# STMP3770 register map
Vendor: Freescale Semiconductor (NXP); Series: STMP37xx; File version: 1.0
CPU: other r0p0, little endian, no MPU, no FPU, 2 interrupt priority bits
Registers are 32-bit, read-write, reset 0x0 unless marked. A register's access mark holds for its fields unless they carry their own. Offsets are from the block's base; [hi:lo] are bit positions.

## I2C — I2C 总线控制器，支持主从模式、PIO/DMA 数据传输、可编程时序与多主机仲裁。
Base 0x80058000
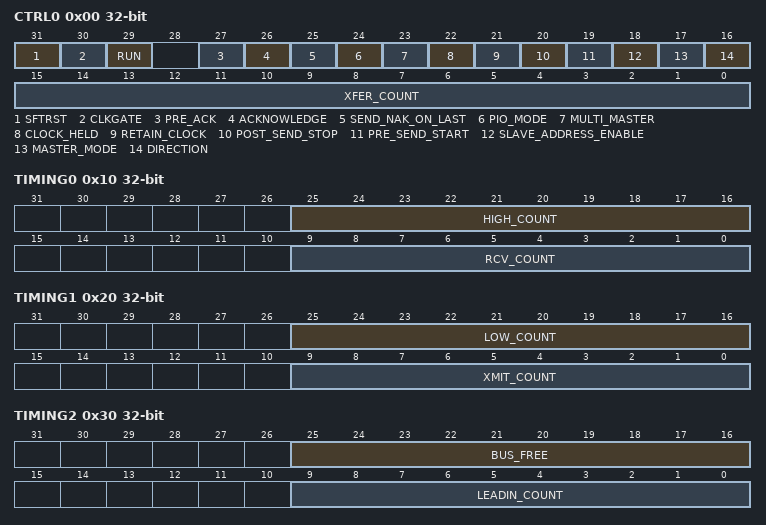
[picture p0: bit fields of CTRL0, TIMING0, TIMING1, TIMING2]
0x00 CTRL0 — I2C 控制寄存器 0，配置传输方向、主从模式、字节数、START/STOP 条件、PIO 模式、时钟门控与软复位等核心参数。
  [31] SFTRST — 软复位：0=正常运行，1=复位整个 I2C 模块。
    0=RUN; 1=RESET
  [30] CLKGATE — 时钟门控：0=正常时钟，1=关闭时钟以节能。
    0=RUN; 1=NO_CLKS
  [29] RUN — 控制器运行控制：0=停止，1=运行。
    0=HALT; 1=RUN
  [27] PRE_ACK — 预应答控制，用于在时钟保持前提前产生 ACK。
  [26] ACKNOWLEDGE — 应答控制：0=发送 NAK，1=发送 ACK。
    0=SNAK; 1=ACK
  [25] SEND_NAK_ON_LAST — 最后一字节是否发送 NAK：0=ACK，1=NAK。
    0=ACK_IT; 1=NAK_IT
  [24] PIO_MODE — PIO 模式使能，用于软件直接控制数据读写。
  [23] MULTI_MASTER — 多主机模式：0=单主机，1=多主机。
    0=SINGLE; 1=MULTIPLE
  [22] CLOCK_HELD — 时钟保持状态：0=释放，1=保持低电平。
    0=RELEASE; 1=HELD_LOW
  [21] RETAIN_CLOCK — 保持 SCL 低电平：0=释放，1=保持低电平。
    0=RELEASE; 1=HOLD_LOW
  [20] POST_SEND_STOP — 传输后是否发送 STOP 条件：0=不发，1=发送 STOP。
    0=NO_STOP; 1=SEND_STOP
  [19] PRE_SEND_START — 传输前是否发送 START 条件：0=不发，1=发送 START。
    0=NO_START; 1=SEND_START
  [18] SLAVE_ADDRESS_ENABLE — 从机地址匹配使能：0=禁用，1=使能。
    0=DISABLED; 1=ENABLED
  [17] MASTER_MODE — 主从模式选择：0=从机，1=主机。
    0=SLAVE; 1=MASTER
  [16] DIRECTION — 传输方向：0=接收，1=发送。
    0=RECEIVE; 1=TRANSMIT
  [15:0] XFER_COUNT — 本次传输的字节数（16 位）。
0x10 TIMING0 — I2C 时序寄存器 0，配置 SCL 高电平周期与接收采样计数。
  [25:16] HIGH_COUNT — SCL 高电平周期计数，决定 SCL 保持高电平的时钟周期数。
  [9:0] RCV_COUNT — 接收采样计数，用于控制接收数据位的采样时序。
0x20 TIMING1 — I2C 时序寄存器 1，配置 SCL 低电平周期与发送采样计数。
  [25:16] LOW_COUNT — SCL 低电平周期计数，决定 SCL 保持低电平的时钟周期数。
  [9:0] XMIT_COUNT — 发送采样计数，用于控制发送数据位的时序。
0x30 TIMING2 — I2C 时序寄存器 2，配置引导计数与总线空闲时间。
  [25:16] BUS_FREE — 总线空闲时间计数，定义两次传输之间总线必须保持空闲的最小时钟周期数。
  [9:0] LEADIN_COUNT — 引导计数，用于 START 条件前的引导时序。
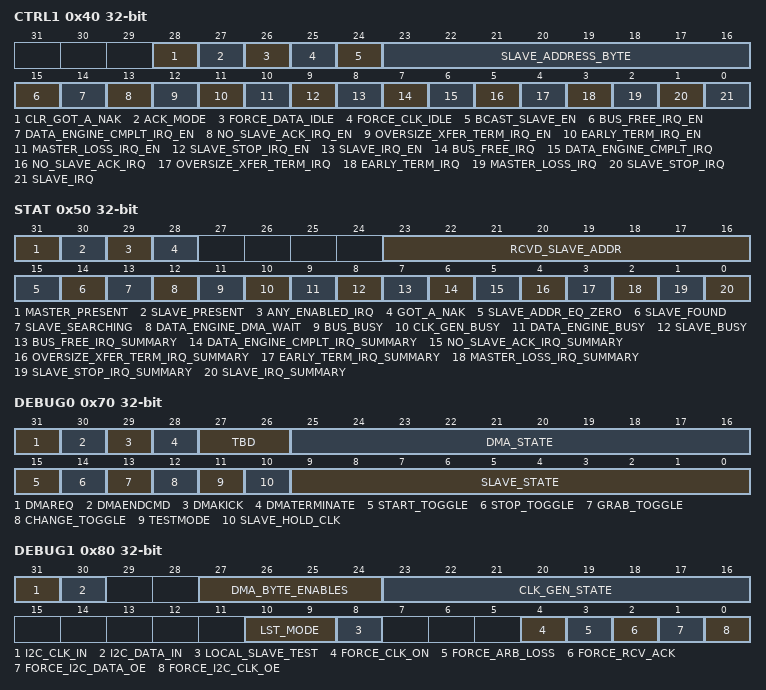
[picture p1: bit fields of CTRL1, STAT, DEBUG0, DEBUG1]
0x40 CTRL1 — I2C 控制寄存器 1，配置各类中断状态/使能、从机地址、广播监听、ACK 模式及清除 NAK 标志。
  [28] CLR_GOT_A_NAK — 清除 GOT_A_NAK 标志：0=无操作，1=清除标志。
    0=DO_NOTHING; 1=CLEAR
  [27] ACK_MODE — ACK 模式：0=在时钟保持低后应答，1=在时钟保持低前应答。
    0=ACK_AFTER_HOLD_LOW; 1=ACK_BEFORE_HOLD_LOW
  [26] FORCE_DATA_IDLE — 强制 SDA 空闲，用于调试时强制数据线进入空闲状态。
  [25] FORCE_CLK_IDLE — 强制 SCL 空闲，用于调试时强制时钟线进入空闲状态。
  [24] BCAST_SLAVE_EN — 广播地址监听：0=忽略广播，1=监听广播地址。
    0=NO_BCAST; 1=WATCH_BCAST
  [23:16] SLAVE_ADDRESS_BYTE — 从机地址字节（8 位），用于配置本机从机地址。
  [15] BUS_FREE_IRQ_EN — 总线空闲中断使能：0=禁用，1=使能。
    0=DISABLED; 1=ENABLED
  [14] DATA_ENGINE_CMPLT_IRQ_EN — 数据引擎完成中断使能：0=禁用，1=使能。
    0=DISABLED; 1=ENABLED
  [13] NO_SLAVE_ACK_IRQ_EN — 无从机应答中断使能：0=禁用，1=使能。
    0=DISABLED; 1=ENABLED
  [12] OVERSIZE_XFER_TERM_IRQ_EN — 超长传输终止中断使能：0=禁用，1=使能。
    0=DISABLED; 1=ENABLED
  [11] EARLY_TERM_IRQ_EN — 提前终止中断使能：0=禁用，1=使能。
    0=DISABLED; 1=ENABLED
  [10] MASTER_LOSS_IRQ_EN — 主机仲裁丢失中断使能：0=禁用，1=使能。
    0=DISABLED; 1=ENABLED
  [9] SLAVE_STOP_IRQ_EN — 从机 STOP 中断使能：0=禁用，1=使能。
    0=DISABLED; 1=ENABLED
  [8] SLAVE_IRQ_EN — 从机访问中断使能：0=禁用，1=使能。
    0=DISABLED; 1=ENABLED
  [7] BUS_FREE_IRQ — 总线空闲中断状态：0=无请求，1=有请求。
    0=NO_REQUEST; 1=REQUEST
  [6] DATA_ENGINE_CMPLT_IRQ — 数据引擎完成中断状态：0=无请求，1=有请求。
    0=NO_REQUEST; 1=REQUEST
  [5] NO_SLAVE_ACK_IRQ — 无从机应答中断状态：0=无请求，1=有请求。
    0=NO_REQUEST; 1=REQUEST
  [4] OVERSIZE_XFER_TERM_IRQ — 超长传输终止中断状态：0=无请求，1=有请求。
    0=NO_REQUEST; 1=REQUEST
  [3] EARLY_TERM_IRQ — 提前终止中断状态：0=无请求，1=有请求。
    0=NO_REQUEST; 1=REQUEST
  [2] MASTER_LOSS_IRQ — 主机仲裁丢失中断状态：0=无请求，1=有请求。
    0=NO_REQUEST; 1=REQUEST
  [1] SLAVE_STOP_IRQ — 从机 STOP 中断状态：0=无请求，1=有请求。
    0=NO_REQUEST; 1=REQUEST
  [0] SLAVE_IRQ — 从机访问中断状态：0=无请求，1=有请求。
    0=NO_REQUEST; 1=REQUEST
0x50 STAT — I2C 状态寄存器，反映各类中断汇总、总线/引擎/时钟忙状态、从机搜索状态及接收到的从机地址等信息。
  [31] MASTER_PRESENT — 主机功能存在标志：0=不可用，1=可用。
    0=UNAVAILABLE; 1=AVAILABLE
  [30] SLAVE_PRESENT — 从机功能存在标志：0=不可用，1=可用。
    0=UNAVAILABLE; 1=AVAILABLE
  [29] ANY_ENABLED_IRQ — 任意已使能中断请求：0=无请求，1=至少有一个中断请求。
    0=NO_REQUESTS; 1=AT_LEAST_ONE_REQUEST
  [28] GOT_A_NAK — 检测到 NAK 标志：0=未检测到，1=检测到 NAK。
    0=NO_NAK; 1=DETECTED_NAK
  [23:16] RCVD_SLAVE_ADDR — 接收到的从机地址字节（8 位）。
  [15] SLAVE_ADDR_EQ_ZERO — 接收到的从机地址是否为 0：0=未匹配到 0，1=地址为 0。
    0=ZERO_NOT_MATCHED; 1=WAS_ZERO
  [14] SLAVE_FOUND — 从机地址匹配结果：0=空闲，1=已匹配并等待。
    0=IDLE; 1=WAITING
  [13] SLAVE_SEARCHING — 从机地址搜索状态：0=空闲，1=正在搜索。
    0=IDLE; 1=ACTIVE
  [12] DATA_ENGINE_DMA_WAIT — 数据引擎 DMA 等待状态：0=继续，1=等待 DMA。
    0=CONTINUE; 1=WAITING
  [11] BUS_BUSY — 总线忙状态：0=空闲，1=忙。
    0=IDLE; 1=BUSY
  [10] CLK_GEN_BUSY — 时钟生成器忙状态：0=空闲，1=忙。
    0=IDLE; 1=BUSY
  [9] DATA_ENGINE_BUSY — 数据引擎忙状态：0=空闲，1=忙。
    0=IDLE; 1=BUSY
  [8] SLAVE_BUSY — 从机引擎忙状态：0=空闲，1=忙。
    0=IDLE; 1=BUSY
  [7] BUS_FREE_IRQ_SUMMARY — 总线空闲中断汇总：0=无请求，1=有请求。
    0=NO_REQUEST; 1=REQUEST
  [6] DATA_ENGINE_CMPLT_IRQ_SUMMARY — 数据引擎完成中断汇总：0=无请求，1=有请求。
    0=NO_REQUEST; 1=REQUEST
  [5] NO_SLAVE_ACK_IRQ_SUMMARY — 无从机应答中断汇总：0=无请求，1=有请求。
    0=NO_REQUEST; 1=REQUEST
  [4] OVERSIZE_XFER_TERM_IRQ_SUMMARY — 超长传输终止中断汇总：0=无请求，1=有请求。
    0=NO_REQUEST; 1=REQUEST
  [3] EARLY_TERM_IRQ_SUMMARY — 提前终止中断汇总：0=无请求，1=有请求。
    0=NO_REQUEST; 1=REQUEST
  [2] MASTER_LOSS_IRQ_SUMMARY — 主机仲裁丢失中断汇总：0=无请求，1=有请求。
    0=NO_REQUEST; 1=REQUEST
  [1] SLAVE_STOP_IRQ_SUMMARY — 从机 STOP 中断汇总：0=无请求，1=有请求。
    0=NO_REQUEST; 1=REQUEST
  [0] SLAVE_IRQ_SUMMARY — 从机访问中断汇总：0=无请求，1=有请求。
    0=NO_REQUEST; 1=REQUEST
0x60 DATA — I2C 数据寄存器，用于 PIO 模式下读写传输数据，或作为 DMA 数据接口。
  [31:0] DATA — PIO/DMA 数据读写端口（32 位），写操作发送数据，读操作接收数据。
0x70 DEBUG0 ro — I2C 调试寄存器 0，提供从机状态机、DMA 状态机、各类事件翻转位及 DMA 控制信号的调试可见性。
  [31] DMAREQ — DMA 请求信号，用于调试时观察 DMA 请求状态。
  [30] DMAENDCMD — DMA 结束命令信号，用于调试时观察 DMA 命令结束状态。
  [29] DMAKICK — DMA 启动信号，用于调试时观察 DMA 传输启动状态。
  [28] DMATERMINATE — DMA 终止信号，用于调试时观察 DMA 传输终止状态。
  [27:26] TBD — 保留位（2 位），供未来扩展或内部测试使用。
  [25:16] DMA_STATE — DMA 状态机当前状态（10 位）。
  [15] START_TOGGLE — START 事件翻转位，用于调试时观察 START 条件事件。
  [14] STOP_TOGGLE — STOP 事件翻转位，用于调试时观察 STOP 条件事件。
  [13] GRAB_TOGGLE — GRAB 事件翻转位，用于调试时观察总线占用事件。
  [12] CHANGE_TOGGLE — CHANGE 事件翻转位，用于调试时观察状态变化事件。
  [11] TESTMODE — 测试模式使能，用于芯片测试时的特殊模式。
  [10] SLAVE_HOLD_CLK — 从机时钟保持状态：0=未保持，1=正在保持 SCL 低电平。
  [9:0] SLAVE_STATE — 从机状态机当前状态（10 位）。
0x80 DEBUG1 ro — I2C 调试寄存器 1，提供强制信号注入、从机测试模式、时钟生成器状态、DMA 字节使能及 I2C 引脚输入状态的调试可见性。
  [31] I2C_CLK_IN — I2C 时钟输入引脚（SCL）的当前电平状态。
  [30] I2C_DATA_IN — I2C 数据输入引脚（SDA）的当前电平状态。
  [27:24] DMA_BYTE_ENABLES — DMA 字节使能掩码（4 位），指示当前 DMA 传输中哪些字节有效。
  [23:16] CLK_GEN_STATE — 时钟生成器状态机当前状态（8 位）。
  [10:9] LST_MODE — 从机监听传输模式：0=广播，1=本机写，2=本机读，3=非本机。
    0=BCAST; 1=MY_WRITE; 2=MY_READ; 3=NOT_ME
  [8] LOCAL_SLAVE_TEST — 本地从机测试模式使能，用于芯片测试时启用内部从机测试逻辑。
  [4] FORCE_CLK_ON — 强制时钟开启，用于调试时强制使能时钟生成器。
  [3] FORCE_ARB_LOSS — 强制仲裁丢失，用于调试时模拟仲裁丢失场景。
  [2] FORCE_RCV_ACK — 强制接收 ACK，用于调试时手动注入 ACK 信号。
  [1] FORCE_I2C_DATA_OE — 强制 I2C 数据输出使能，用于调试时手动控制 SDA 输出。
  [0] FORCE_I2C_CLK_OE — 强制 I2C 时钟输出使能，用于调试时手动控制 SCL 输出。
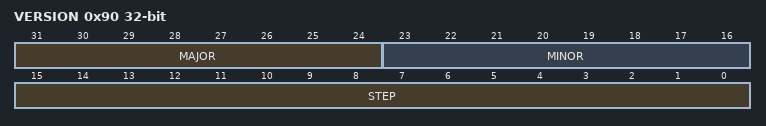
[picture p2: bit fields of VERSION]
0x90 VERSION ro — I2C 版本寄存器，记录 IP 核的主版本、次版本和步进版本号。
  [31:24] MAJOR — 主版本号（8 位）。
  [23:16] MINOR — 次版本号（8 位）。
  [15:0] STEP — 步进版本号（16 位），标识当前 IP 的修订步进。
